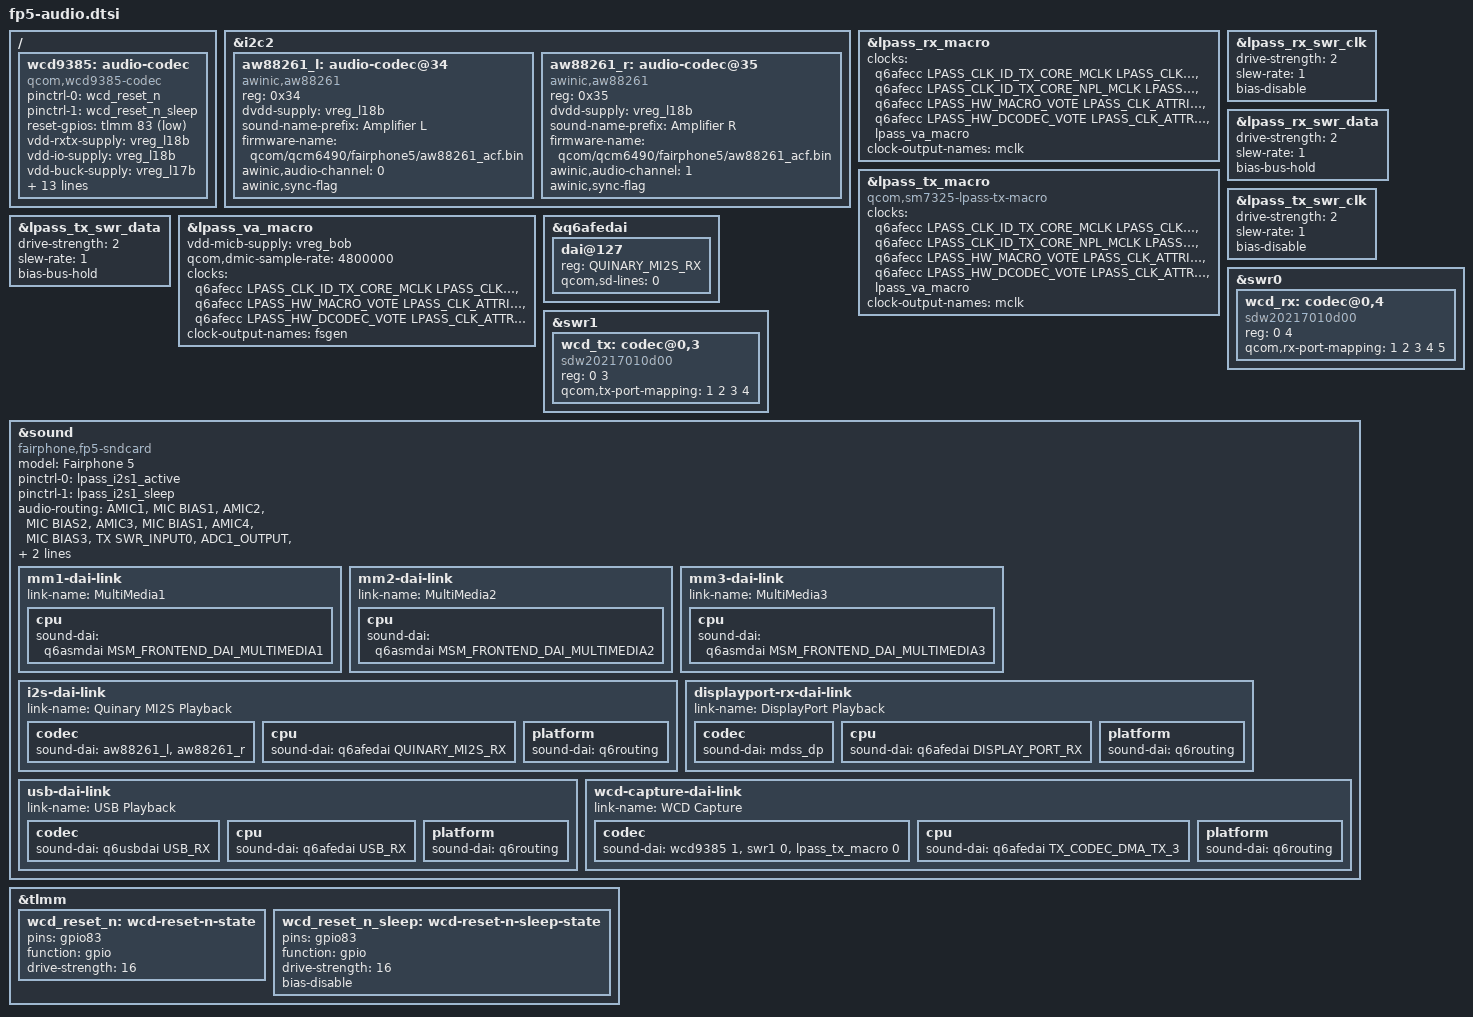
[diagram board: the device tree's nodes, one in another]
// SPDX-License-Identifier: BSD-3-Clause
/*
 * Fairphone 5 audio, from sc7280-mainline's qcm6490-fairphone-fp5.dts.
 * Mainline has every driver this needs (aw88261, wcd938x, lpass rx/tx
 * macros) but not the board wiring.
 *
 * Written as label references so it does not depend on line numbers or
 * surrounding text. If mainline renames or drops any label used here, dtc
 * fails with "Reference to non-existent node or label" instead of silently
 * building a kernel with no sound.
 */

/ {
	wcd9385: audio-codec {
		compatible = "qcom,wcd9385-codec";

		pinctrl-0 = <&wcd_reset_n>;
		pinctrl-1 = <&wcd_reset_n_sleep>;
		pinctrl-names = "default", "sleep";

		reset-gpios = <&tlmm 83 GPIO_ACTIVE_LOW>;

		vdd-rxtx-supply = <&vreg_l18b>;
		vdd-io-supply = <&vreg_l18b>;
		vdd-buck-supply = <&vreg_l17b>;
		vdd-mic-bias-supply = <&vreg_bob>;

		qcom,micbias1-microvolt = <1800000>;
		qcom,micbias2-microvolt = <1800000>;
		qcom,micbias3-microvolt = <1800000>;
		qcom,micbias4-microvolt = <1800000>;

		qcom,mbhc-buttons-vthreshold-microvolt = <75000 150000 237000 500000 500000
							  500000 500000 500000>;
		qcom,mbhc-headset-vthreshold-microvolt = <1700000>;
		qcom,mbhc-headphone-vthreshold-microvolt = <50000>;

		qcom,rx-device = <&wcd_rx>;
		qcom,tx-device = <&wcd_tx>;

		#sound-dai-cells = <1>;
	};
};

&i2c2 {
	status = "okay";

	aw88261_l: audio-codec@34 {
		compatible = "awinic,aw88261";
		reg = <0x34>;

		dvdd-supply = <&vreg_l18b>;
		sound-name-prefix = "Amplifier L";
		firmware-name = "qcom/qcm6490/fairphone5/aw88261_acf.bin";

		awinic,audio-channel = <0>;
		awinic,sync-flag;

		#sound-dai-cells = <0>;
	};

	aw88261_r: audio-codec@35 {
		compatible = "awinic,aw88261";
		reg = <0x35>;

		dvdd-supply = <&vreg_l18b>;
		sound-name-prefix = "Amplifier R";
		firmware-name = "qcom/qcm6490/fairphone5/aw88261_acf.bin";

		awinic,audio-channel = <1>;
		awinic,sync-flag;

		#sound-dai-cells = <0>;
	};
};

&lpass_rx_macro {
	status = "okay";
};

&lpass_rx_macro {
	/delete-property/ power-domains;
	/delete-property/ power-domain-names;
	clocks = <&q6afecc LPASS_CLK_ID_TX_CORE_MCLK LPASS_CLK_ATTRIBUTE_COUPLE_NO>,
		 <&q6afecc LPASS_CLK_ID_TX_CORE_NPL_MCLK LPASS_CLK_ATTRIBUTE_COUPLE_NO>,
		 <&q6afecc LPASS_HW_MACRO_VOTE LPASS_CLK_ATTRIBUTE_COUPLE_NO>,
		 <&q6afecc LPASS_HW_DCODEC_VOTE LPASS_CLK_ATTRIBUTE_COUPLE_NO>,
		 <&lpass_va_macro>;
	clock-names = "mclk",
		      "npl",
		      "macro",
		      "dcodec",
		      "fsgen";

	clock-output-names = "mclk";
};

&lpass_rx_swr_clk {
	drive-strength = <2>;
	slew-rate = <1>;
	bias-disable;
};

&lpass_rx_swr_data {
	drive-strength = <2>;
	slew-rate = <1>;
	bias-bus-hold;
};

&lpass_tx_macro {
	status = "okay";
};

&lpass_tx_macro {
	compatible = "qcom,sm7325-lpass-tx-macro",
		     "qcom,sm8450-lpass-tx-macro"; // txmacro = v9.2

	/delete-property/ power-domains;
	/delete-property/ power-domain-names;
	clocks = <&q6afecc LPASS_CLK_ID_TX_CORE_MCLK LPASS_CLK_ATTRIBUTE_COUPLE_NO>,
		 <&q6afecc LPASS_CLK_ID_TX_CORE_NPL_MCLK LPASS_CLK_ATTRIBUTE_COUPLE_NO>,
		 <&q6afecc LPASS_HW_MACRO_VOTE LPASS_CLK_ATTRIBUTE_COUPLE_NO>,
		 <&q6afecc LPASS_HW_DCODEC_VOTE LPASS_CLK_ATTRIBUTE_COUPLE_NO>,
		 <&lpass_va_macro>;
	clock-names = "mclk",
		      "npl",
		      "macro",
		      "dcodec",
		      "fsgen";

	clock-output-names = "mclk";
};

&lpass_tx_swr_clk {
	drive-strength = <2>;
	slew-rate = <1>;
	bias-disable;
};

&lpass_tx_swr_data {
	drive-strength = <2>;
	slew-rate = <1>;
	bias-bus-hold;
};

&lpass_va_macro {
	vdd-micb-supply = <&vreg_bob>;

	/* No DMIC used on Fairphone 5 */
	qcom,dmic-sample-rate = <4800000>;

	status = "okay";
};

&lpass_va_macro {
	/delete-property/ power-domains;
	/delete-property/ power-domain-names;
	clocks = <&q6afecc LPASS_CLK_ID_TX_CORE_MCLK LPASS_CLK_ATTRIBUTE_COUPLE_NO>,
		 <&q6afecc LPASS_HW_MACRO_VOTE LPASS_CLK_ATTRIBUTE_COUPLE_NO>,
		 <&q6afecc LPASS_HW_DCODEC_VOTE LPASS_CLK_ATTRIBUTE_COUPLE_NO>;
	clock-names = "mclk",
		      "macro",
		      "dcodec";

	clock-output-names = "fsgen";
};

&q6afedai {
	dai@127 {
		reg = <QUINARY_MI2S_RX>;
		qcom,sd-lines = <0>;
	};
};

&swr0 {
	status = "okay";

	wcd_rx: codec@0,4 {
		compatible = "sdw20217010d00";
		reg = <0 4>;
		qcom,rx-port-mapping = <1 2 3 4 5>;
	};
};

&swr1 {
	status = "okay";

	wcd_tx: codec@0,3 {
		compatible = "sdw20217010d00";
		reg = <0 3>;
		qcom,tx-port-mapping = <1 2 3 4>;
	};
};

&sound {
	compatible = "fairphone,fp5-sndcard";
	model = "Fairphone 5";

	pinctrl-0 = <&lpass_i2s1_active>;
	pinctrl-1 = <&lpass_i2s1_sleep>;
	pinctrl-names = "default",
			"sleep";

	audio-routing = "AMIC1", "MIC BIAS1",
			"AMIC2", "MIC BIAS2",
			"AMIC3", "MIC BIAS1",
			"AMIC4", "MIC BIAS3",
			"TX SWR_INPUT0", "ADC1_OUTPUT",
			"TX SWR_INPUT1", "ADC2_OUTPUT",
			"TX SWR_INPUT4", "ADC3_OUTPUT",
			"TX SWR_INPUT5", "ADC4_OUTPUT";

	mm1-dai-link {
		link-name = "MultiMedia1";

		cpu {
			sound-dai = <&q6asmdai MSM_FRONTEND_DAI_MULTIMEDIA1>;
		};
	};

	mm2-dai-link {
		link-name = "MultiMedia2";

		cpu {
			sound-dai = <&q6asmdai MSM_FRONTEND_DAI_MULTIMEDIA2>;
		};
	};

	mm3-dai-link {
		link-name = "MultiMedia3";

		cpu {
			sound-dai = <&q6asmdai MSM_FRONTEND_DAI_MULTIMEDIA3>;
		};
	};

	i2s-dai-link {
		link-name = "Quinary MI2S Playback";

		codec {
			sound-dai = <&aw88261_l>, <&aw88261_r>;
		};

		cpu {
			sound-dai = <&q6afedai QUINARY_MI2S_RX>;
		};

		platform {
			sound-dai = <&q6routing>;
		};
	};

	displayport-rx-dai-link {
		link-name = "DisplayPort Playback";

		codec {
			sound-dai = <&mdss_dp>;
		};

		cpu {
			sound-dai = <&q6afedai DISPLAY_PORT_RX>;
		};

		platform {
			sound-dai = <&q6routing>;
		};
	};

	usb-dai-link {
		link-name = "USB Playback";

		codec {
			sound-dai = <&q6usbdai USB_RX>;
		};

		cpu {
			sound-dai = <&q6afedai USB_RX>;
		};

		platform {
			sound-dai = <&q6routing>;
		};
	};

	wcd-capture-dai-link {
		link-name = "WCD Capture";

		codec {
			sound-dai = <&wcd9385 1>, <&swr1 0>, <&lpass_tx_macro 0>;
		};

		cpu {
			sound-dai = <&q6afedai TX_CODEC_DMA_TX_3>;
		};

		platform {
			sound-dai = <&q6routing>;
		};
	};
};

&tlmm {
	wcd_reset_n: wcd-reset-n-state {
		pins = "gpio83";
		function = "gpio";
		drive-strength = <16>;
	};

	wcd_reset_n_sleep: wcd-reset-n-sleep-state {
		pins = "gpio83";
		function = "gpio";
		drive-strength = <16>;
		bias-disable;
	};
};
